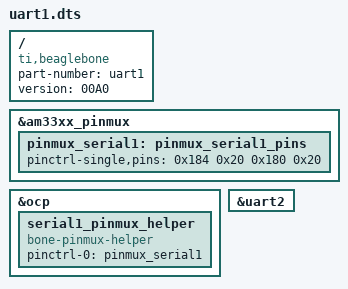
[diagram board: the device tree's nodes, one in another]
/*
 * Copyright (C) 2013 CircuitCo
 * Copyright (C) 2013 Texas Instruments
 *
 * This program is free software; you can redistribute it and/or modify
 * it under the terms of the GNU General Public License version 2 as
 * published by the Free Software Foundation.
 */
/dts-v1/;
/plugin/;

/ {
	compatible = "ti,beaglebone", "ti,beaglebone-black";

	/* identification */
	part-number = "uart1";
	version = "00A0";

	fragment@0 {
		target = <&am33xx_pinmux>;
		__overlay__ {
			pinmux_serial1: pinmux_serial1_pins {
				pinctrl-single,pins = <
                    0x184  0x20     /* P9_24 (ZCZ ball D15) RX-enabled MODE 0 */
                    0x180  0x20     /* P9_26 (ZCZ ball D16) RX-enabled MODE 0 */
                >;
			};
		};
	};

	fragment@1 {
		target = <&ocp>;
		__overlay__ {
            serial1_pinmux_helper {
                compatible  = "bone-pinmux-helper";
                status      = "okay";
                pinctrl-names	= "default";
	        	pinctrl-0	= <&pinmux_serial1>;
			};
		};
	};

	fragment@2 {
		target = <&uart2>;          /* really uart1 */
		__overlay__ {
			status 		= "okay";
		};
	};
};
